# S6E1A1 register map
File version: 1.1
Registers are 8-bit, read-write, reset 0x0 unless marked. A register's access mark holds for its fields unless they carry their own. Offsets are from the block's base; lines under a group give offsets from that group; [hi:lo] are bit positions; {n}, {i} and the like mark numbered series; 'fields as' and 'values as' point back to an identical list; <NAME> marks a mode.

## Memory map
0x40000000 FLASHIF blocks up to offset 0x104 — Flash Memory
0x40000200 UID blocks up to offset 0x8 — Unique ID
0x40010000 CLOCK blocks up to offset 0x69 — Clock Unit Registers
0x40011000 HWWDT blocks up to offset 0xC04 — Hardware Watchdog Timer
0x40012000 SWWDT blocks up to offset 0xC04 — Software Watchdog Timer
0x40015000 DTIM blocks up to offset 0x3C — Dual Timer
0x40020000 MFT0 blocks up to offset 0x1EA — Multifunction Timer 0
0x40024000 MFT_PPG blocks up to offset 0x381 — PPG Configuration Registers
0x40025000 BT0 blocks up to offset 0x12 — Base Timer 0
0x40025100 BTIOSEL03 size 0x2 — Base Timer I/O Select
0x40025F00 SBSSR blocks up to offset 0xFE — Software-based Simultaneous Startup Register
0x40026000 QPRC0 blocks up to offset 0x40 — Quadrature Position/Revolution Counter 0
0x40026100 QPRC0_NF blocks up to offset 0xA
0x40027000 ADC0 blocks up to offset 0x54 — ADC0 Registers
0x4002E000 CRTRIM blocks up to offset 0x10 — CR Trimming Registers
0x40030000 EXTI blocks up to offset 0x1A — External Interrupt and NMI Control
0x40031000 INTREQ_A blocks up to offset 0x94 — Interrupts
0x40033000 GPIO blocks up to offset 0x940 — General-purpose I/O ports
0x40035000 LVD blocks up to offset 0x11 — Low-voltage Detection
0x40035100 DS blocks up to offset 0x810 — Low Power Consumption Mode Registers
0x40038000 MFS0 blocks up to offset 0x42 — MFS REgisters
0x40039000 CRC blocks up to offset 0x10 — CRC Registers
0x4003A000 WC blocks up to offset 0x15 — Watch Counter
0x4003B000 RTC blocks up to offset 0x31 — REAL-TIME CLOCK
0x4003C000 LSCRP size 0x1 — Low-speed CR Prescaler Register
0x4003C100 PCG blocks up to offset 0x28 — Peripheral Clock Gating Registers
0x40060000 DMAC blocks up to offset 0x90 — DMAC Registers
0xF0001000 MTB_DWT blocks up to offset 0x1000 — Micro Trace Buffer Data Watchpoint and Trace Registers
0xF8000000 FASTIO size 0x100 — FASTIO Registers

## Interrupts
0 CSV (CLOCK)
1 SWDT (SWWDT)
2 LVD
3 WFG_DTIF (MFT0)
4 EXINT0_7 (EXTI)
6 DTIM_QDU (DTIM, QPRC0)
7 MFS0RX (MFS0)
8 MFS0TX (MFS0)
19 DMAC0 (DMAC)
20 DMAC1 (DMAC)
23 PPG (MFT_PPG)
24 OSC_PLL_WC_RTC (CLOCK, WC, RTC)
25 ADC0
28 FRTIM (MFT0)
29 INCAP (MFT0)
30 OUTCOMP (MFT0)
31 BTIM0_3_FLASH (FLASHIF, BT0)

## FLASHIF — Flash Memory
Base 0x40000000
0x04 FRWTR reset 0x1 — Flash Read Wait Register
  [1:0] RWT — Read Wait Cycle
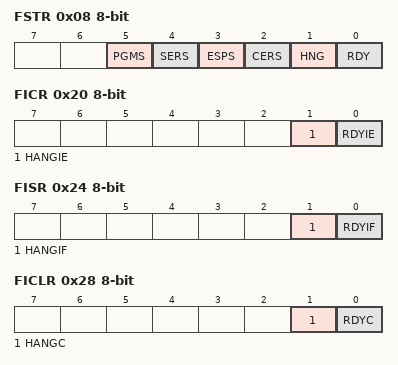
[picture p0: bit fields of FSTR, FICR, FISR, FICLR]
0x08 FSTR ro — Flash Status Register
  [5] PGMS — Flash Program Status
  [4] SERS — Flash Sector Erase Status
  [3] ESPS — Flash Erase Suspend Status
  [2] CERS — Flash Chip Erase Status
  [1] HNG — Flash Hang Status
  [0] RDY — Flash Ready Status
0x10 FSYNDN reset 0x1 — Flash Sync Down Register
  [3:0] SD — 0
0x20 FICR — Flash Interrupt Control Register
  [1] HANGIE — HANG Interrupt Enable
  [0] RDYIE — RDY Interrupt Enable
0x24 FISR ro — Flash Interrupt Status Register
  [1] HANGIF — HANG Interrupt Flag
  [0] RDYIF — RDY Interrupt Flag
0x28 FICLR wo — Flash Interrupt Clear Register
  [1] HANGC — HANG Interrupt Clear
  [0] RDYC — RDY Interrupt Clear
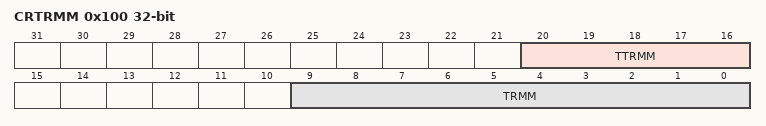
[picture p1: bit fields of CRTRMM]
0x100 CRTRMM 32-bit ro — CR Trimming Data Mirror Register
  [20:16] TTRMM — CR Temperature Trimming Data Mirror Bit
  [9:0] TRMM — CR Trimming Data Mirror Bit

## UID — Unique ID
Base 0x40000200
0x00 UIDR0 32-bit ro — Unique ID Register 0
  [31:4] UID — $nique ID Register 0
0x04 UIDR1 32-bit ro — Unique ID Register 1
  [12:0] UID — Unique ID 40 to Unique ID 28

## HWWDT — Hardware Watchdog Timer
Base 0x40011000
0x00 WDG_LDR 32-bit reset 0xFFFF — Hardware Watchdog Timer Load Register
0x04 WDG_VLR 32-bit ro — Hardware Watchdog Timer Value Register
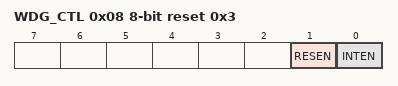
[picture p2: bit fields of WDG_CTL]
0x08 WDG_CTL reset 0x3 — Hardware Watchdog Timer Control Register
  [1] RESEN — Hardware watchdog reset enable bit
  [0] INTEN — Hardware watchdog interrupt and counter enable bit
0x0C WDG_ICL — Hardware Watchdog Timer Clear Register
0x10 WDG_RIS ro — Hardware Watchdog Timer Interrupt Status Register
  [0] RIS — Hardware watchdog interrupt status bit
0xC00 WDG_LCK 32-bit reset 0x1 — Hardware Watchdog Timer Lock Register

## Notices in the file
Licence Terms
Copyright (C) 2013 Spansion LLC. All Rights Reserved.
This software is owned and published by:
Spansion LLC, 915 DeGuigne Dr. Sunnyvale, CA  94088-3453 ("Spansion").
BY DOWNLOADING, INSTALLING OR USING THIS SOFTWARE, YOU AGREE TO BE BOUND
BY ALL THE TERMS AND CONDITIONS OF THIS AGREEMENT.
This software contains source code for use with Spansion
components. This software is licensed by Spansion to be adapted only
for use in systems utilizing Spansion components. Spansion shall not be
responsible for misuse or illegal use of this software for devices not
supported herein.  Spansion is providing this software "AS IS" and will
not be responsible for issues arising from incorrect user implementation
of the software.
SPANSION MAKES NO WARRANTY, EXPRESS OR IMPLIED, ARISING BY LAW OR OTHERWISE,
REGARDING THE SOFTWARE (INCLUDING ANY ACOOMPANYING WRITTEN MATERIALS),
ITS PERFORMANCE OR SUITABILITY FOR YOUR INTENDED USE, INCLUDING,
WITHOUT LIMITATION, THE IMPLIED WARRANTY OF MERCHANTABILITY, THE IMPLIED
WARRANTY OF FITNESS FOR A PARTICULAR PURPOSE OR USE, AND THE IMPLIED
WARRANTY OF NONINFRINGEMENT.
SPANSION SHALL HAVE NO LIABILITY (WHETHER IN CONTRACT, WARRANTY, TORT,
NEGLIGENCE OR OTHERWISE) FOR ANY DAMAGES WHATSOEVER (INCLUDING, WITHOUT
LIMITATION, DAMAGES FOR LOSS OF BUSINESS PROFITS, BUSINESS INTERRUPTION,
LOSS OF BUSINESS INFORMATION, OR OTHER PECUNIARY LOSS) ARISING FROM USE OR
INABILITY TO USE THE SOFTWARE, INCLUDING, WITHOUT LIMITATION, ANY DIRECT,
INDIRECT, INCIDENTAL, SPECIAL OR CONSEQUENTIAL DAMAGES OR LOSS OF DATA,
SAVINGS OR PROFITS,
EVEN IF SPANSION HAS BEEN ADVISED OF THE POSSIBILITY OF SUCH DAMAGES.
YOU ASSUME ALL RESPONSIBILITIES FOR SELECTION OF THE SOFTWARE TO ACHIEVE YOUR
INTENDED RESULTS, AND FOR THE INSTALLATION OF, USE OF, AND RESULTS OBTAINED
FROM, THE SOFTWARE.
This software may be replicated in part or whole for the licensed use,
with the restriction that this Disclaimer and Copyright notice must be
included with each copy of this software, whether used in part or whole,
at all times.
